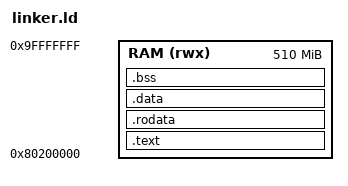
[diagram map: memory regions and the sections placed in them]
OUTPUT_ARCH(riscv)
ENTRY(_start)

MEMORY
{
    RAM (rwx) : ORIGIN = 0x80200000, LENGTH = 510M
}

SECTIONS
{
    __kernel_start = .;

    .text : ALIGN(4096)
    {
        KEEP(*(.text.boot))
        *(.text .text.*)
    } > RAM

    .rodata : ALIGN(4096)
    {
        *(.rodata .rodata.*)
        *(.srodata .srodata.*)
    } > RAM

    .data : ALIGN(4096)
    {
        *(.data .data.*)
        *(.sdata .sdata.*)
    } > RAM

    .bss (NOLOAD) : ALIGN(4096)
    {
        __bss_start = .;
        *(.bss.stack)
        *(.bss .bss.*)
        *(.sbss .sbss.*)
        *(COMMON)
        . = ALIGN(16);
        __bss_end = .;
    } > RAM

    . = ALIGN(4096);
    __kernel_end = .;

    /DISCARD/ :
    {
        *(.eh_frame .eh_frame.*)
        *(.comment)
    }
}

ASSERT(__kernel_end < 0xa0000000, "kernel exceeds available RAM")
